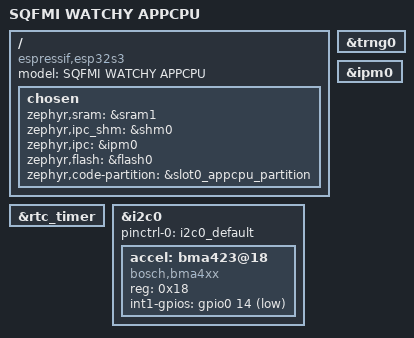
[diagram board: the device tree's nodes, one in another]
/*
 * Copyright (c) 2023 Espressif Systems (Shanghai) Co., Ltd.
 *
 * SPDX-License-Identifier: Apache-2.0
 */
/dts-v1/;

#include <espressif/esp32s3/esp32s3_mini_n8.dtsi>
#include <espressif/partitions_0x0_amp.dtsi>
#include "watchy-pinctrl.dtsi"

/ {
	model = "SQFMI WATCHY APPCPU";
	compatible = "espressif,esp32s3";

	chosen {
		zephyr,sram = &sram1;
		zephyr,ipc_shm = &shm0;
		zephyr,ipc = &ipm0;
		zephyr,flash = &flash0;
		zephyr,code-partition = &slot0_appcpu_partition;
	};
};

&trng0 {
	status = "okay";
};

&ipm0 {
	status = "okay";
};

&rtc_timer {
	status = "okay";
};

&i2c0 {
	pinctrl-0 = <&i2c0_default>;
	pinctrl-names = "default";
	accel: bma423@18 {
		compatible = "bosch,bma4xx";
		reg = <0x18>;
		int1-gpios = <&gpio0 14 GPIO_ACTIVE_LOW>;
	};
	status = "okay";
};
